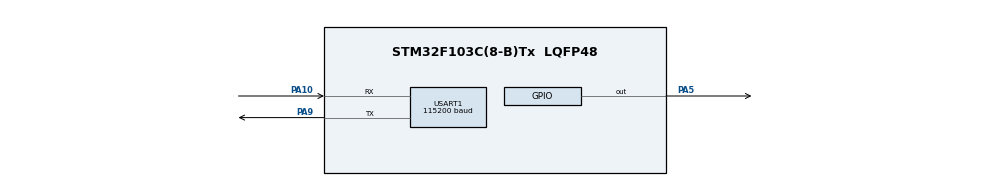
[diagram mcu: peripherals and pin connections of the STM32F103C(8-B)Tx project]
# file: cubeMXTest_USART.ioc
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Dma.Request0=USART1_RX
Dma.Request1=USART1_TX
Dma.USART1_RX.0.Direction=DMA_PERIPH_TO_MEMORY
Dma.USART1_RX.0.Instance=DMA1_Channel5
Dma.USART1_RX.0.MemDataAlignment=DMA_MDATAALIGN_BYTE
Dma.USART1_RX.0.MemInc=DMA_MINC_ENABLE
Dma.USART1_RX.0.Mode=DMA_NORMAL
Dma.USART1_RX.0.PeriphDataAlignment=DMA_PDATAALIGN_BYTE
Dma.USART1_RX.0.PeriphInc=DMA_PINC_DISABLE
Dma.USART1_RX.0.Priority=DMA_PRIORITY_LOW
Dma.USART1_TX.1.Direction=DMA_MEMORY_TO_PERIPH
Dma.USART1_TX.1.Instance=DMA1_Channel4
Dma.USART1_TX.1.MemDataAlignment=DMA_MDATAALIGN_BYTE
Dma.USART1_TX.1.MemInc=DMA_MINC_ENABLE
Dma.USART1_TX.1.Mode=DMA_CIRCULAR
Dma.USART1_TX.1.PeriphDataAlignment=DMA_PDATAALIGN_BYTE
Dma.USART1_TX.1.PeriphInc=DMA_PINC_DISABLE
Dma.USART1_TX.1.Priority=DMA_PRIORITY_LOW
Mcu.Family=STM32F1
Mcu.Name=STM32F103C(8-B)Tx
Mcu.Package=LQFP48
NVIC.DMA1_Channel4_IRQn=true\:0\:0\:false\:true\:true\:1\:false\:true
NVIC.DMA1_Channel5_IRQn=true\:0\:0\:false\:true\:true\:2\:false\:true
NVIC.PriorityGroup=NVIC_PRIORITYGROUP_4
NVIC.USART1_IRQn=true\:0\:0\:false\:true\:true\:3\:true\:true
PA10.Mode=Asynchronous
PA10.Signal=USART1_RX
PA13.Mode=Serial_Wire
PA13.Signal=SYS_JTMS-SWDIO
PA14.Mode=Serial_Wire
PA14.Signal=SYS_JTCK-SWCLK
PA5.Signal=GPIO_Output
PA9.Mode=Asynchronous
PA9.Signal=USART1_TX
PD0-OSC_IN.Mode=HSE-External-Oscillator
PD0-OSC_IN.Signal=RCC_OSC_IN
PD1-OSC_OUT.Mode=HSE-External-Oscillator
PD1-OSC_OUT.Signal=RCC_OSC_OUT
ProjectManager.HeapSize=0x200
ProjectManager.StackSize=0x400
ProjectManager.TargetToolchain=Makefile
RCC.APB1Freq_Value=8000000
RCC.APB2Freq_Value=8000000
USART1.BaudRate=115200
USART1.VirtualMode=VM_ASYNC
board=custom

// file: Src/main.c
/* USER CODE BEGIN Header */
/**
  ******************************************************************************
  * @file           : main.c
  * @brief          : Main program body
  ******************************************************************************
  * @attention
  *
  * <h2><center>&copy; Copyright (c) 2019 STMicroelectronics.
  * All rights reserved.</center></h2>
  *
  * This software component is licensed by ST under BSD 3-Clause license,
  * the "License"; You may not use this file except in compliance with the
  * License. You may obtain a copy of the License at:
  *                        opensource.org/licenses/BSD-3-Clause
  *
  ******************************************************************************
  */
/* USER CODE END Header */

#include "main.h"
#include "dma.h"
#include "usart.h"
#include "gpio.h"
#include <stdio.h>
#include <stdlib.h>
#include <string.h>

/* USER CODE BEGIN PD */
uint8_t rData[1];
uint8_t tData1[] = "This is a test message from stm32:\n\r";
uint8_t tData2[] = "HUANG ZHE CHOU ZHU\n\r";
uint8_t endline[] = "\n\r";
uint8_t a = 0;
uint8_t a_str[10];
/* USER CODE END PD */

void SystemClock_Config(void);
static void MX_NVIC_Init(void);
/* USER CODE BEGIN PFP */
//#ifdef __GNUC__
//  #define PUTCHAR_PROTOTYPE int __io_putchar(int ch)
//#else
  #define PUTCHAR_PROTOTYPE int fputc(int ch, FILE *f)
//#endif /* __GNUC__ */

/* USER CODE END PFP */

/* USER CODE BEGIN 0 */
int fputc(int ch,FILE *f)
{
  //while(HAL_UART_GetState(&huart1) == HAL_UART_STATE_BUSY_TX);
  HAL_UART_Transmit(&huart1,(uint8_t *)&ch,1,0xFFFF);
  return ch;
}

int fgetc(FILE *f)
{
  uint8_t ch = 0;
  HAL_UART_Receive(&huart1, &ch, 1, 0xffff);
  return ch;
}

void LEDSwitchOn(GPIO_TypeDef* LedPort, uint16_t LedPin)
{
  HAL_GPIO_WritePin(LedPort,LedPin,1);
}

void endLine()
{
  HAL_UART_Transmit(&huart1, endline, sizeof(endline), 1000);
  while(HAL_UART_GetState(&huart1) == HAL_UART_STATE_BUSY_TX);
}
/* USER CODE END 0 */

int main(void)
{

  /* MCU Configuration--------------------------------------------------------*/

  /* Reset of all peripherals, Initializes the Flash interface and the Systick. */
  HAL_Init();

  /* Configure the system clock */
  SystemClock_Config();

  /* Initialize all configured peripherals */
  MX_GPIO_Init();
  MX_DMA_Init();
  MX_USART1_UART_Init();

  /* Initialize interrupts */
  MX_NVIC_Init();

  /* Infinite loop */
  while (1)
  {

    //接收数据控制LED
    /* USER CODE BEGIN 3 */
    /*if (HAL_UART_GetState(&huart1) == HAL_UART_STATE_BUSY_TX){
      LEDSwitchOn(GPIOA, GPIO_PIN_5);
    }*/

    //计数
    /*itoa(a,a_str,10);
    HAL_UART_Transmit(&huart1, a_str, sizeof(a_str), 1000);
    while(HAL_UART_GetState(&huart1) == HAL_UART_STATE_BUSY_TX);
    endLine();
    a++;*/

    //发送字符串
    HAL_UART_Transmit(&huart1, tData1, sizeof(tData1), 1000);
    while(HAL_UART_GetState(&huart1) == HAL_UART_STATE_BUSY_TX);
    HAL_UART_Transmit(&huart1, tData2, sizeof(tData2), 1000);
    while(HAL_UART_GetState(&huart1) == HAL_UART_STATE_BUSY_TX);
    //printf("Printf1\n\r");
    //printf("Printf2\n\r");

    /*
    //接收字符串,并原文发送
    HAL_UART_Receive(&huart1, rData, sizeof(rData), 1000);
    while(HAL_UART_GetState(&huart1) == HAL_UART_STATE_BUSY_RX);
    HAL_UART_Transmit(&huart1, rData, sizeof(rData), 1000);
    while(HAL_UART_GetState(&huart1) == HAL_UART_STATE_BUSY_TX);
    HAL_Delay(500);
    memset(rData,0,sizeof(rData));*/
  }
  /* USER CODE END 3 */
}

void SystemClock_Config(void)
{
  RCC_OscInitTypeDef RCC_OscInitStruct = {0};
  RCC_ClkInitTypeDef RCC_ClkInitStruct = {0};

  /** Initializes the CPU, AHB and APB busses clocks
  */
  RCC_OscInitStruct.OscillatorType = RCC_OSCILLATORTYPE_HSI;
  RCC_OscInitStruct.HSIState = RCC_HSI_ON;
  RCC_OscInitStruct.HSICalibrationValue = RCC_HSICALIBRATION_DEFAULT;
  RCC_OscInitStruct.PLL.PLLState = RCC_PLL_NONE;
  if (HAL_RCC_OscConfig(&RCC_OscInitStruct) != HAL_OK)
  {
    Error_Handler();
  }
  /** Initializes the CPU, AHB and APB busses clocks
  */
  RCC_ClkInitStruct.ClockType = RCC_CLOCKTYPE_HCLK|RCC_CLOCKTYPE_SYSCLK
                              |RCC_CLOCKTYPE_PCLK1|RCC_CLOCKTYPE_PCLK2;
  RCC_ClkInitStruct.SYSCLKSource = RCC_SYSCLKSOURCE_HSI;
  RCC_ClkInitStruct.AHBCLKDivider = RCC_SYSCLK_DIV1;
  RCC_ClkInitStruct.APB1CLKDivider = RCC_HCLK_DIV1;
  RCC_ClkInitStruct.APB2CLKDivider = RCC_HCLK_DIV1;

  if (HAL_RCC_ClockConfig(&RCC_ClkInitStruct, FLASH_LATENCY_0) != HAL_OK)
  {
    Error_Handler();
  }
}

/**
  * @brief NVIC Configuration.
  * @retval None
  */
static void MX_NVIC_Init(void)
{
  /* DMA1_Channel4_IRQn interrupt configuration */
  HAL_NVIC_SetPriority(DMA1_Channel4_IRQn, 0, 0);
  HAL_NVIC_EnableIRQ(DMA1_Channel4_IRQn);
  /* DMA1_Channel5_IRQn interrupt configuration */
  HAL_NVIC_SetPriority(DMA1_Channel5_IRQn, 0, 0);
  HAL_NVIC_EnableIRQ(DMA1_Channel5_IRQn);
  /* USART1_IRQn interrupt configuration */
  HAL_NVIC_SetPriority(USART1_IRQn, 0, 0);
  HAL_NVIC_EnableIRQ(USART1_IRQn);
}

void Error_Handler(void)
{
}

/************************ (C) COPYRIGHT STMicroelectronics *****END OF FILE****/
